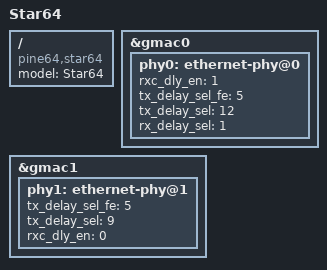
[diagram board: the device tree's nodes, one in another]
// SPDX-License-Identifier: GPL-2.0 OR MIT
/*
 * Copyright (C) 2022 StarFive Technology Co., Ltd.
 * Copyright (C) 2022 Hal Feng <hal.feng@starfivetech.com>
 */

/dts-v1/;
#include "jh7110-star64.dtsi"

/ {
	model = "Star64";
	compatible = "pine64,star64", "starfive,jh7110";
};

&gmac0 {
	#address-cells = <1>;
	#size-cells = <0>;
	status = "okay";
	phy0: ethernet-phy@0 {
		rxc_dly_en = <1>;
		tx_delay_sel_fe = <5>;
		tx_delay_sel = <12>;
		rx_delay_sel = <1>;
	};
};
 
&gmac1 {
	#address-cells = <1>;
	#size-cells = <0>;
	status = "okay";
	phy1: ethernet-phy@1 {
		tx_delay_sel_fe = <5>;
		tx_delay_sel = <9>;
		rxc_dly_en = <0>;
	};
};
